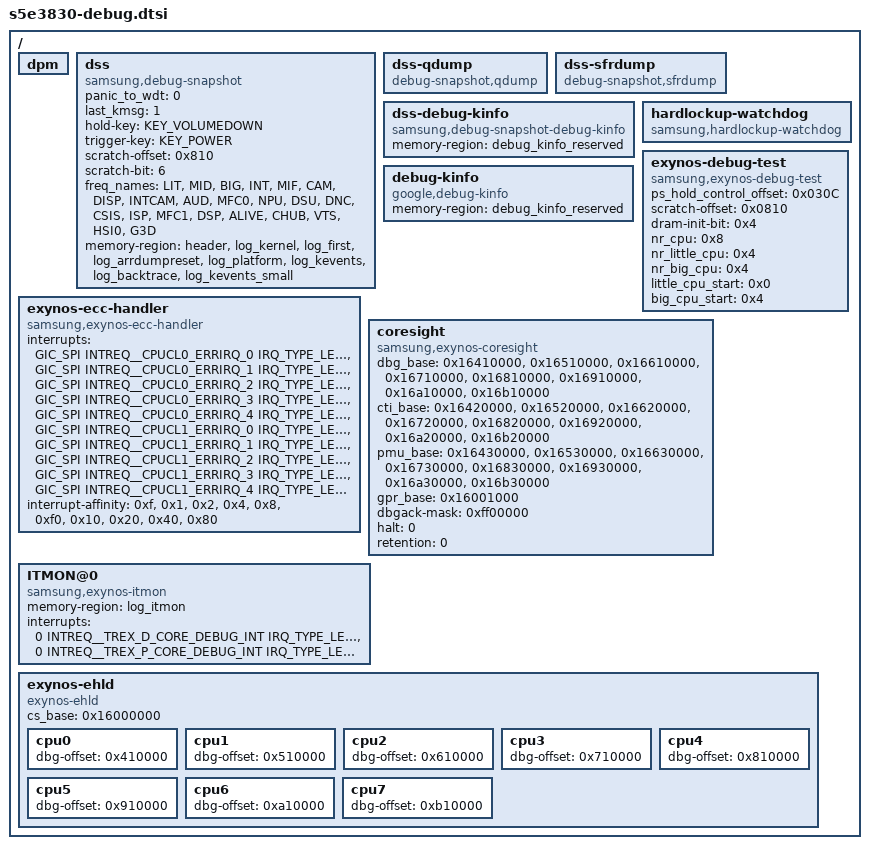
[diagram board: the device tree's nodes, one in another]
// SPDX-License-Identifier: GPL-2.0-only

#include <dt-bindings/interrupt-controller/s5e3830.h>
#include <dt-bindings/input/linux-event-codes.h>

/ {
	dpm: dpm {
	};

	dss: dss {
		compatible = "samsung,debug-snapshot";
		panic_to_wdt = <0>;
		last_kmsg = <1>;
		hold-key = <KEY_VOLUMEDOWN>;
		trigger-key = <KEY_POWER>;
		scratch-offset = <0x810>; /* SYSIP_DAT0 */
		scratch-bit = <6>;
//		wa-pre-reading-ecc-sysreg = <0x82000530>, <0x10000>, <0>, <0>;
		freq_names = "LIT", "MID", "BIG", "INT", "MIF", "CAM",
				"DISP", "INTCAM", "AUD", "MFC0", "NPU", "DSU",
				"DNC", "CSIS", "ISP", "MFC1", "DSP", "ALIVE",
				"CHUB", "VTS", "HSI0", "G3D";
		memory-region = <&header>, <&log_kernel>,
				<&log_first>, <&log_arrdumpreset>, <&log_platform>,
				<&log_kevents>, <&log_backtrace>, <&log_kevents_small>;
	};

	dss-qdump {
		compatible = "debug-snapshot,qdump";
	};

	dss-sfrdump {
		compatible = "debug-snapshot,sfrdump";
		/* -----------<< Example >>-------------------
		dump-info {
			#address-cells = <1>;
			#size-cells = <1>;

			gic-setenable {
				reg = <0x11f01100 0x100>;
			};
			gic-setpend {
				reg = <0x11f01200 0x100>;
			};
			gic-setactive {
				reg = <0x11f01300 0x100>;
			};
		};
		*/
	};

	dss-debug-kinfo {
		compatible = "samsung,debug-snapshot-debug-kinfo";
		memory-region = <&debug_kinfo_reserved>;
	};

	debug-kinfo {
		compatible = "google,debug-kinfo";
		memory-region = <&debug_kinfo_reserved>;
	};

	hardlockup-watchdog {
		compatible = "samsung,hardlockup-watchdog";
	};

	exynos-debug-test {
		compatible = "samsung,exynos-debug-test";
		ps_hold_control_offset = <0x030C>;
		scratch-offset = <0x0810>; /* SYSIP_DAT0 */
		dram-init-bit = <0x4>;
		nr_cpu = <0x8>;
		nr_little_cpu = <0x4>;
		nr_big_cpu = <0x4>;
		little_cpu_start = <0x0>;
		big_cpu_start = <0x4>;
	};

	exynos-ecc-handler {
		compatible = "samsung,exynos-ecc-handler";
		interrupts =	<GIC_SPI INTREQ__CPUCL0_ERRIRQ_0 IRQ_TYPE_LEVEL_HIGH>,
				<GIC_SPI INTREQ__CPUCL0_ERRIRQ_1 IRQ_TYPE_LEVEL_HIGH>,
				<GIC_SPI INTREQ__CPUCL0_ERRIRQ_2 IRQ_TYPE_LEVEL_HIGH>,
				<GIC_SPI INTREQ__CPUCL0_ERRIRQ_3 IRQ_TYPE_LEVEL_HIGH>,
				<GIC_SPI INTREQ__CPUCL0_ERRIRQ_4 IRQ_TYPE_LEVEL_HIGH>,
				<GIC_SPI INTREQ__CPUCL1_ERRIRQ_0 IRQ_TYPE_LEVEL_HIGH>,
				<GIC_SPI INTREQ__CPUCL1_ERRIRQ_1 IRQ_TYPE_LEVEL_HIGH>,
				<GIC_SPI INTREQ__CPUCL1_ERRIRQ_2 IRQ_TYPE_LEVEL_HIGH>,
				<GIC_SPI INTREQ__CPUCL1_ERRIRQ_3 IRQ_TYPE_LEVEL_HIGH>,
				<GIC_SPI INTREQ__CPUCL1_ERRIRQ_4 IRQ_TYPE_LEVEL_HIGH>;
		interrupt-names =	"DSU(CL0), L3 DATA or TAG or Snoop filter RAM (Uncorrected Error)",
					"CORE0, L1 DATA or TAG RAM (Uncorrected Error)",
					"CORE1, L1 DATA or TAG RAM (Uncorrected Error)",
					"CORE2, L1 DATA or TAG RAM (Uncorrected Error)",
					"CORE3, L1 DATA or TAG RAM (Uncorrected Error)",
					"DSU(CL1), L3 DATA or TAG or Snoop filter RAM (Uncorrected Error)",
					"CORE4, L1 DATA or TAG RAM (Uncorrected Error)",
					"CORE5, L1 DATA or TAG RAM (Uncorrected Error)",
					"CORE6, L1 DATA or TAG RAM (Uncorrected Error)",
					"CORE7, L1 DATA or TAG RAM (Uncorrected Error)";
		interrupt-affinity = <0xf>, <0x1>, <0x2>, <0x4>, <0x8>,
				     <0xf0>, <0x10>, <0x20>, <0x40>, <0x80>;
	};

	coresight {
		compatible = "samsung,exynos-coresight";
		dbg_base = <0x16410000>, <0x16510000>, <0x16610000>, <0x16710000>,
			 <0x16810000>, <0x16910000>, <0x16a10000>, <0x16b10000>;
		cti_base = <0x16420000>, <0x16520000>, <0x16620000>, <0x16720000>,
			 <0x16820000>, <0x16920000>, <0x16a20000>, <0x16b20000>;
		pmu_base = <0x16430000>, <0x16530000>, <0x16630000>, <0x16730000>,
			 <0x16830000>, <0x16930000>, <0x16a30000>, <0x16b30000>;
		gpr_base = <0x16001000>;
		dbgack-mask = <0xff00000>;
		halt = <0>;
		retention = <0>;
	};

	ITMON@0 {
		compatible = "samsung,exynos-itmon";
		memory-region = <&log_itmon>;
		interrupts = <0 INTREQ__TREX_D_CORE_DEBUG_INT IRQ_TYPE_LEVEL_HIGH>,
			     <0 INTREQ__TREX_P_CORE_DEBUG_INT IRQ_TYPE_LEVEL_HIGH>;
		status = "ok";
	};

	exynos-ehld {
		compatible = "exynos-ehld";
		#address-cells = <1>;
		#size-cells = <1>;
		cs_base = <0x16000000>;

		cpu0 {
			dbg-offset = <0x410000>;
		};
		cpu1 {
			dbg-offset = <0x510000>;
		};
		cpu2 {
			dbg-offset = <0x610000>;
		};
		cpu3 {
			dbg-offset = <0x710000>;
		};
		cpu4 {
			dbg-offset = <0x810000>;
		};
		cpu5 {
			dbg-offset = <0x910000>;
		};
		cpu6 {
			dbg-offset = <0xa10000>;
		};
		cpu7 {
			dbg-offset = <0xb10000>;
		};
	};
};
